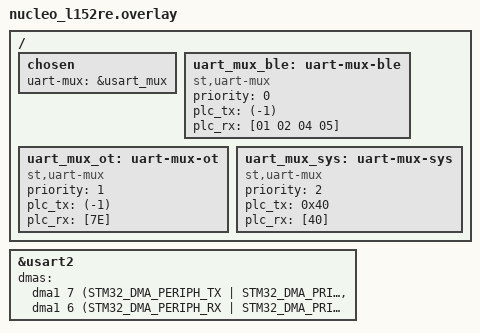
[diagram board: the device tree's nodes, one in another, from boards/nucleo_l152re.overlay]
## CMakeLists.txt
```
# SPDX-License-Identifier: Apache-2.0

cmake_minimum_required(VERSION 3.20.0)

# Add the parent directory to the DTS search path
# CMAKE_CURRENT_SOURCE_DIR is the folder containing this CMakeLists.txt
set(DTS_ROOT ${CMAKE_CURRENT_SOURCE_DIR}/..)

# Manually include the board-specific runner settings
if(EXISTS "${CMAKE_CURRENT_SOURCE_DIR}/boards/${BOARD}.cmake")
    include("${CMAKE_CURRENT_SOURCE_DIR}/boards/${BOARD}.cmake")
endif()

find_package(Zephyr REQUIRED HINTS $ENV{ZEPHYR_BASE})
project(uart_mux_test)

target_sources(app PRIVATE
	../src/uart_mux.c
	../src/log_backend_uart_mux.c
	src/main.c
)

target_include_directories(app PRIVATE
	../src
)
```

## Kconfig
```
source "Kconfig.zephyr"

source "rcp_ble_ot/src/Kconfig.uart_mux"

config UART_MUX_TEST
	bool "UART mux test application"
	default y

config TEST_BLE_EVENT_PERIOD_MS
	int "Protocol A event period (ms)"
	default 500

config TEST_OT_EVENT_PERIOD_MS
	int "Protocol B event period (ms)"
	default 1000

config TEST_SYS_PERIOD_MS
	int "System heartbeat period (ms)"
	default 2000
```

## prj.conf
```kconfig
#
# Core
#
CONFIG_MAIN_STACK_SIZE=2048
CONFIG_SYSTEM_WORKQUEUE_STACK_SIZE=1024
CONFIG_HEAP_MEM_POOL_SIZE=0

#
# UART
#
CONFIG_UART_ASYNC_API=y
CONFIG_UART_INTERRUPT_DRIVEN=n

#
# Logging / console
#
# Disable console & polling UART usage. It is not possible to use it with virtual UART.
CONFIG_CONSOLE=n
CONFIG_UART_CONSOLE=n
CONFIG_BOOT_BANNER=n

# Enable logging
CONFIG_LOG=y
CONFIG_LOG_MODE_DEFERRED=y
CONFIG_LOG_DEFAULT_LEVEL=3
CONFIG_LOG_OUTPUT=y

# Log backend infrastructure
CONFIG_LOG_BACKEND_UART=n

CONFIG_LOG_BUFFER_SIZE=2048
CONFIG_LOG_PROCESS_THREAD_CUSTOM_PRIORITY=y
CONFIG_LOG_PROCESS_THREAD_STACK_SIZE=2048
CONFIG_LOG_PROCESS_THREAD_PRIORITY=5
CONFIG_LOG_PROCESS_TRIGGER_THRESHOLD=1

# Needed by logging
CONFIG_PRINTK=y

#
# GPIO (LED)
#
CONFIG_GPIO=y

#
# UART mux (application-level)
#
CONFIG_UART_MUX=y
#CONFIG_UART_MUX_TX_SLAB_COUNT=4
CONFIG_UART_MUX_RX_BUF_SIZE=128

#
# Test behavior (used by main.c)
#
CONFIG_TEST_BLE_EVENT_PERIOD_MS=500
CONFIG_TEST_OT_EVENT_PERIOD_MS=1000
CONFIG_TEST_SYS_PERIOD_MS=2000

# Debug
CONFIG_DEBUG=y
#CONFIG_NO_OPTIMIZATIONS=y
CONFIG_COMPILER_SAVE_TEMPS=y
```

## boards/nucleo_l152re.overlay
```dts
usart_mux: &usart2 {
	dmas = <&dma1 7 (STM32_DMA_PERIPH_TX | STM32_DMA_PRIORITY_HIGH)>,
	       <&dma1 6 (STM32_DMA_PERIPH_RX | STM32_DMA_PRIORITY_HIGH)>;
	dma-names = "tx", "rx";
	status = "okay";
};
/ {
	chosen {

		/delete-property/ zephyr,console; /* No console support with virtual UART */
		uart-mux = &usart_mux;
		};

	uart_mux_ble: uart-mux-ble {
		compatible = "st,uart-mux";
		status = "okay";
		priority = <0>;

		/* PLC comes from first payload byte */
		plc_tx = <(-1)>;
		plc_rx = [01 02 04 05];
	};

	uart_mux_ot: uart-mux-ot {
		compatible = "st,uart-mux";
		status = "okay";
		priority = <1>;

		plc_tx = <(-1)>;
		plc_rx = [7E];
	};

	uart_mux_sys: uart-mux-sys {
		compatible = "st,uart-mux";
		status = "okay";
		priority = <2>;

		plc_tx = <0x40>;
		plc_rx = [40];
	};
};
```

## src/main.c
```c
#include <zephyr/kernel.h>
#include <zephyr/device.h>
#include <zephyr/drivers/uart.h>
#include <zephyr/sys/printk.h>
#include <zephyr/drivers/gpio.h>
#include <zephyr/logging/log.h>
#include <zephyr/logging/log_backend.h>

LOG_MODULE_REGISTER(uart_mux_test, LOG_LEVEL_INF);

/* ===================== Devices ===================== */

static const struct device *uart_ble =
	DEVICE_DT_GET(DT_NODELABEL(uart_mux_ble));
static const struct device *uart_ot =
	DEVICE_DT_GET(DT_NODELABEL(uart_mux_ot));
static const struct device *uart_sys =
	DEVICE_DT_GET(DT_NODELABEL(uart_mux_sys));
/* ===================== LED ===================== */

#define LED_NODE DT_ALIAS(led0)
static const struct gpio_dt_spec led =
	GPIO_DT_SPEC_GET(LED_NODE, gpios);

/* ===================== RX buffers ===================== */

static uint8_t ble_rx_buf[64];
static uint8_t ot_rx_buf[128];
static uint8_t sys_rx_buf[64];

/* ===================== UART callbacks ===================== */

static void ble_uart_cb(const struct device *dev,
			struct uart_event *evt,
			void *user_data)
{
	if (evt->type == UART_RX_RDY) {
		/* Respond with fixed "event" */
		uint8_t rsp[] = { evt->data.rx.buf[0], 0x0E, 0x00 };
		uart_tx(dev, rsp, sizeof(rsp), SYS_FOREVER_MS);
	}
}

static void ot_uart_cb(const struct device *dev,
		       struct uart_event *evt,
		       void *user_data)
{
	if (evt->type == UART_RX_RDY) {
		/* Echo payload back */
		uart_tx(dev,
			evt->data.rx.buf,
			evt->data.rx.len,
			SYS_FOREVER_MS);
	}
}

static void sys_uart_cb(const struct device *dev,
			struct uart_event *evt,
			void *user_data)
{
	if (evt->type == UART_RX_RDY) {
		gpio_pin_toggle_dt(&led);
	}
}

/* ===================== Threads ===================== */

void ble_thread(void)
{
	uint8_t evt[] = { 0x01, 0x0E, 0x01, 0x00 };

	while (1) {
		uart_tx(uart_ble, evt, sizeof(evt), SYS_FOREVER_MS);
		k_sleep(K_MSEC(CONFIG_TEST_BLE_EVENT_PERIOD_MS));
	}
}

void ot_thread(void)
{
	uint8_t frame[] = { 0x7E, 0xAA, 0x55, 0x00 };

	while (1) {
		frame[3]++;
		uart_tx(uart_ot, frame, sizeof(frame), SYS_FOREVER_MS);
		k_sleep(K_MSEC(CONFIG_TEST_OT_EVENT_PERIOD_MS));
	}
}

void sys_thread(void)
{
	char msg[32];

	while (1) {
		int len = snprintk(msg, sizeof(msg),
				   "SYS %u\r\n",
				   k_uptime_get_32());
		uart_tx(uart_sys, msg, len, SYS_FOREVER_MS);
		k_sleep(K_MSEC(CONFIG_TEST_SYS_PERIOD_MS));
	}
}

/* ===================== Thread definitions ===================== */
K_THREAD_DEFINE(ble_tid, 1024, ble_thread, NULL, NULL, NULL,
		5, 0, 0);

K_THREAD_DEFINE(ot_tid, 1024, ot_thread, NULL, NULL, NULL,
		5, 0, 0);

K_THREAD_DEFINE(sys_tid, 1024, sys_thread, NULL, NULL, NULL,
		7, 0, 0);
/* ===================== Main ===================== */
int main(void)
{
	__ASSERT(device_is_ready(uart_ble), "BLE UART not ready");
	__ASSERT(device_is_ready(uart_ot), "OT UART not ready");
	__ASSERT(device_is_ready(uart_sys), "SYS UART not ready");

	gpio_pin_configure_dt(&led, GPIO_OUTPUT_INACTIVE);

#if 0
	k_sleep(K_MSEC(10));
	int count = 0;
	while (1) {
		printk("%-06d: Loop %d\r\n", (int32_t) k_uptime_get(), ++count);
		k_sleep(K_MSEC(10));
	}
#endif
	uart_callback_set(uart_ble, ble_uart_cb, NULL);
	uart_callback_set(uart_ot, ot_uart_cb, NULL);
	uart_callback_set(uart_sys, sys_uart_cb, NULL);

	uart_rx_enable(uart_ble, ble_rx_buf, sizeof(ble_rx_buf), 100);
	uart_rx_enable(uart_ot, ot_rx_buf, sizeof(ot_rx_buf), 100);
	uart_rx_enable(uart_sys, sys_rx_buf, sizeof(sys_rx_buf), 100);

	printk("UART mux test started\n");

	return 0;
}
```
